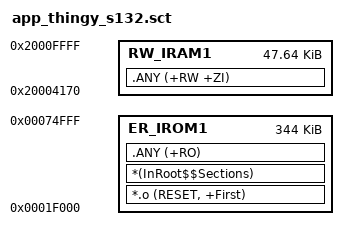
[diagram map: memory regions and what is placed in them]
; *************************************************************
; *** Scatter-Loading Description File generated by uVision ***
; *************************************************************

LR_IROM1 0x0001F000 0x00056000  {    ; load region size_region
  ER_IROM1 0x0001F000 0x00056000  {  ; load address = execution address
   *.o (RESET, +First)
   *(InRoot$$Sections)
   .ANY (+RO)
  }
  RW_IRAM1 0x20004170 0x0000BE90  {  ; RW data
   .ANY (+RW +ZI)
  }
}

